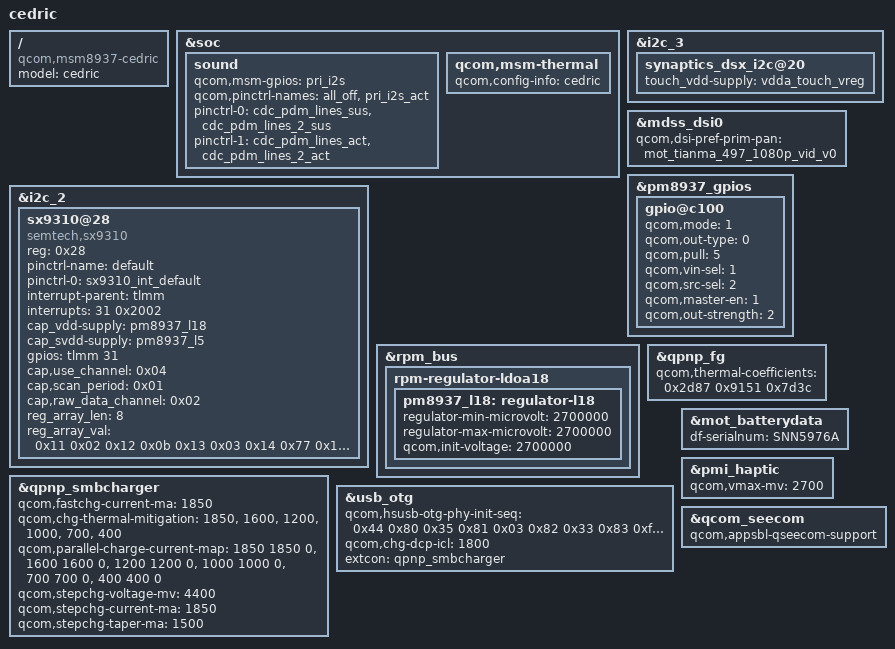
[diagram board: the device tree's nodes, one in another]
/* Copyright (c) 2016, Motorola Mobility Inc. All rights reserved.
 *
 * This program is free software; you can redistribute it and/or modify
 * it under the terms of the GNU General Public License version 2 and
 * only version 2 as published by the Free Software Foundation.
 *
 * This program is distributed in the hope that it will be useful,
 * but WITHOUT ANY WARRANTY; without even the implied warranty of
 * MERCHANTABILITY or FITNESS FOR A PARTICULAR PURPOSE.  See the
 * GNU General Public License for more details.
 *
 *===========================
 * Forward port to 4.9
 * by Vaisakh Murali
 *===========================
 * Cleanup by wiktorek140
 */

#include "msm8937-moto-common-cedric-montana.dtsi"
#include "dsi-panel-mot-tianma-497-1080p-video.dtsi"
#include "dsi-panel-mot-inx-497-1080p-video.dtsi"
#include "msm8937-camera-sensor-mot-overlay.dtsi"
#include "msm8937-cedric-fps-overlay.dtsi"

 / {
	model = "cedric";
	compatible = "qcom,msm8937-cedric", "qcom,msm8937-moto",
			"qcom,msm8937";
};

&soc {
	sound {
		/delete-property/ qcom,cdc-us-euro-gpios;
		/delete-property/ qcom,msm-micbias1-ext-cap;
		/delete-property/ qcom,msm-micbias2-ext-cap;

		qcom,msm-gpios =
			"pri_i2s";
		qcom,pinctrl-names =
			"all_off",
			"pri_i2s_act";
		pinctrl-names =
			"all_off",
			"pri_i2s_act";
		pinctrl-0 = <&cdc_pdm_lines_sus &cdc_pdm_lines_2_sus>;
		pinctrl-1 = <&cdc_pdm_lines_act &cdc_pdm_lines_2_act>;
		/delete-property/ pinctrl-2;
		/delete-property/ pinctrl-3;
		/delete-property/ pinctrl-4;
		/delete-property/ pinctrl-5;
		/delete-property/ pinctrl-6;
		/delete-property/ pinctrl-7;
	};

	qcom,msm-thermal {
		qcom,config-info = "cedric";
	};
};

&i2c_2 {
	sx9310@28 {
		compatible = "semtech,sx9310";
		reg = <0x28>;
		pinctrl-name = "default";
		pinctrl-0 = <&sx9310_int_default>;
		interrupt-parent = <&tlmm>;
		interrupts = <31 0x2002>;
		cap_vdd-supply = <&pm8937_l18>;
		cap_svdd-supply = <&pm8937_l5>;
		gpios = <&tlmm 31 0x2008>; /* IRQ */
		cap,use_channel = <0x04>;
		cap,scan_period = <0x01>;
		cap,raw_data_channel = <0x02>;
		reg_array_len = <8>;
		reg_array_val = <0x11 0x02 0x12 0x0b 0x13 0x03 0x14 0x77 0x15 0x81 0x18 0x5e 0x19 0x10 0x1a 0x04>;
	};
};

&i2c_3 {
	synaptics_dsx_i2c@20 {
		touch_vdd-supply = <&vdda_touch_vreg>;
	};
};

&mdss_dsi0 {
	qcom,dsi-pref-prim-pan = <&mot_tianma_497_1080p_vid_v0>;
};

&pm8937_gpios {
	gpio@c100 {
		status = "ok";
		qcom,mode = <1>;
		qcom,out-type = <0>;
		qcom,pull = <5>;
		qcom,vin-sel = <1>;
		qcom,src-sel = <2>;
		qcom,master-en = <1>;
		qcom,out-strength = <2>;
	};
};

&rpm_bus {
	rpm-regulator-ldoa18 {
		status = "okay";
		pm8937_l18: regulator-l18 {
			regulator-min-microvolt = <2700000>;
			regulator-max-microvolt = <2700000>;
			qcom,init-voltage = <2700000>;
			status = "okay";
		};
	};
};

&qpnp_smbcharger {
	qcom,fastchg-current-ma = <1850>;
	qcom,chg-thermal-mitigation = <1850>, <1600>, <1200>, <1000>,
				      <700>, <400>;
	qcom,parallel-charge-current-map = <1850 1850 0>,
					   <1600 1600 0>,
					   <1200 1200 0>,
					   <1000 1000 0>,
					   <700 700 0>,
					   <400 400 0>;
	qcom,stepchg-voltage-mv = <4400>;
	qcom,stepchg-current-ma = <1850>;
	qcom,stepchg-taper-ma = <1500>;
	/delete-property/ qcom,enable-hvdcp-9v;
};

&qpnp_fg {
	qcom,thermal-coefficients =  /bits/ 16 <0x2d87 0x9151 0x7d3c>;
};

&usb_otg {
	qcom,hsusb-otg-phy-init-seq =
		<0x44 0x80 0x35 0x81 0x03 0x82 0x33 0x83 0xffffffff>;
	qcom,chg-dcp-icl = <1800>;
	extcon = <&qpnp_smbcharger>;
};

&mot_batterydata {
	df-serialnum = "SNN5976A";
	#include "batterydata-gk40-atl.dtsi"
};

&pmi_haptic {
	qcom,vmax-mv = <2700>;
};

&qcom_seecom {
	/delete-property/ qcom,commonlib64-loaded-by-uefi;
	qcom,appsbl-qseecom-support;
};
